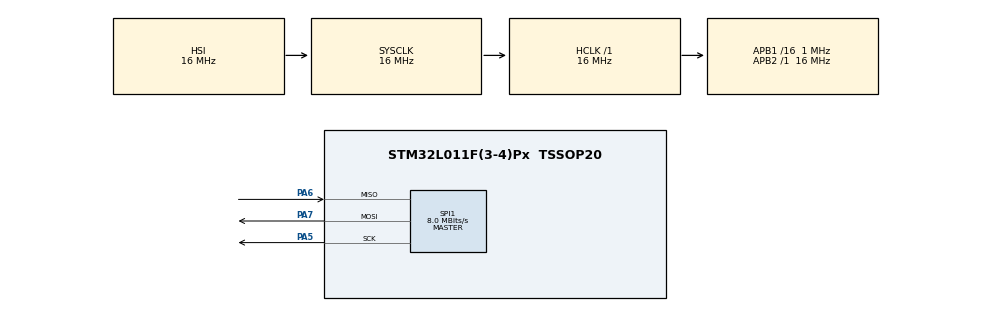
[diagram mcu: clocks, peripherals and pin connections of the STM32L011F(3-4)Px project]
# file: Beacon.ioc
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CRC.CRCLength=CRC_POLYLENGTH_8B
CRC.DefaultInitValueUse=DEFAULT_INIT_VALUE_DISABLE
CRC.DefaultPolynomialUse=DEFAULT_POLYNOMIAL_DISABLE
CRC.InitValue=0x00
CRC.InputDataFormat=CRC_INPUTDATA_FORMAT_BYTES
Mcu.Family=STM32L0
Mcu.Name=STM32L011F(3-4)Px
Mcu.Package=TSSOP20
NVIC.RTC_IRQn=true\:0\:0\:false\:false\:true\:true\:true
PA5.Mode=Full_Duplex_Master
PA5.Signal=SPI1_SCK
PA6.Mode=Full_Duplex_Master
PA6.Signal=SPI1_MISO
PA7.Mode=Full_Duplex_Master
PA7.Signal=SPI1_MOSI
ProjectManager.HeapSize=0x200
ProjectManager.StackSize=0x400
ProjectManager.TargetToolchain=STM32CubeIDE
RCC.AHBFreq_Value=16000000
RCC.APB1CLKDivider=RCC_HCLK_DIV16
RCC.APB1Freq_Value=1000000
RCC.APB1TimFreq_Value=2000000
RCC.APB2Freq_Value=16000000
RCC.APB2TimFreq_Value=16000000
RCC.HCLKFreq_Value=16000000
RCC.HSE_VALUE=8000000
RCC.HSI16_VALUE=16000000
RCC.HSI_VALUE=16000000
RCC.LSE_VALUE=32768
RCC.LptimClockSelection=RCC_LPTIM1CLKSOURCE_LSI
RCC.MSI_VALUE=2097000
RCC.SYSCLKFreq_VALUE=16000000
RCC.SYSCLKSource=RCC_SYSCLKSOURCE_HSI
RCC.VCOOutputFreq_Value=48000000
RTC.Alarm-Alarm\ A=RTC_ALARM_A
RTC.AlarmMaskDateWeekDay-Alarm\ A=RTC_ALARMMASK_DATEWEEKDAY
RTC.AlarmMaskHours-Alarm\ A=RTC_ALARMMASK_HOURS
RTC.AlarmMaskMinutes-Alarm\ A=RTC_ALARMMASK_MINUTES
RTC.AlarmMaskSeconds-Alarm\ A=RTC_ALARMMASK_SECONDS
RTC.Format=RTC_FORMAT_BIN
SPI1.CalculateBaudRate=8.0 MBits/s
SPI1.Direction=SPI_DIRECTION_2LINES
SPI1.Mode=SPI_MODE_MASTER
SPI1.VirtualType=VM_MASTER
VP_CRC_VS_CRC.Mode=CRC_Activate
VP_RTC_VS_RTC_Activate.Mode=RTC_Enabled
VP_RTC_VS_RTC_Alarm_A_Intern.Mode=Alarm A
VP_RTC_VS_RTC_Calendar.Mode=RTC_Calendar
board=custom

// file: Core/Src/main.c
/* USER CODE BEGIN Header */
/**
  ******************************************************************************
  * @file           : main.c
  * @brief          : Main program body
  ******************************************************************************
  * @attention
  *
  * <h2><center>&copy; Copyright (c) 2020 STMicroelectronics.
  * All rights reserved.</center></h2>
  *
  * This software component is licensed by ST under BSD 3-Clause license,
  * the "License"; You may not use this file except in compliance with the
  * License. You may obtain a copy of the License at:
  *                        opensource.org/licenses/BSD-3-Clause
  *
  ******************************************************************************
  */
/* USER CODE END Header */

#include "main.h"

/* USER CODE BEGIN Includes */
#include "program.h"
#include "nrf24.h"
/* USER CODE END Includes */

CRC_HandleTypeDef hcrc;

RTC_HandleTypeDef hrtc;

SPI_HandleTypeDef hspi1;

void SystemClock_Config(void);
static void MX_RTC_Init(void);
static void MX_GPIO_Init(void);
static void MX_SPI1_Init(void);
static void MX_CRC_Init(void);

int main(void)
{

  /* MCU Configuration--------------------------------------------------------*/

  /* Reset of all peripherals, Initializes the Flash interface and the Systick. */
  HAL_Init();

  /* Configure the system clock */
  SystemClock_Config();

  /* Initialize all configured peripherals */
  MX_RTC_Init();
  MX_GPIO_Init();
  MX_SPI1_Init();
  MX_CRC_Init();
  /* USER CODE BEGIN 2 */
  NRF24_Init();
  /* USER CODE END 2 */

  /* Infinite loop */
  /* USER CODE BEGIN WHILE */
  setup();
  while (1)
  {
    /* USER CODE END WHILE */

  }
}

void SystemClock_Config(void)
{
  RCC_OscInitTypeDef RCC_OscInitStruct = {0};
  RCC_ClkInitTypeDef RCC_ClkInitStruct = {0};
  RCC_PeriphCLKInitTypeDef PeriphClkInit = {0};

  /** Configure the main internal regulator output voltage
  */
  __HAL_PWR_VOLTAGESCALING_CONFIG(PWR_REGULATOR_VOLTAGE_SCALE1);
  /** Initializes the CPU, AHB and APB busses clocks
  */
  RCC_OscInitStruct.OscillatorType = RCC_OSCILLATORTYPE_HSI|RCC_OSCILLATORTYPE_LSI;
  RCC_OscInitStruct.HSIState = RCC_HSI_ON;
  RCC_OscInitStruct.HSICalibrationValue = RCC_HSICALIBRATION_DEFAULT;
  RCC_OscInitStruct.LSIState = RCC_LSI_ON;
  RCC_OscInitStruct.PLL.PLLState = RCC_PLL_NONE;
  if (HAL_RCC_OscConfig(&RCC_OscInitStruct) != HAL_OK)
  {
    Error_Handler();
  }
  /** Initializes the CPU, AHB and APB busses clocks
  */
  RCC_ClkInitStruct.ClockType = RCC_CLOCKTYPE_HCLK|RCC_CLOCKTYPE_SYSCLK
                              |RCC_CLOCKTYPE_PCLK1|RCC_CLOCKTYPE_PCLK2;
  RCC_ClkInitStruct.SYSCLKSource = RCC_SYSCLKSOURCE_HSI;
  RCC_ClkInitStruct.AHBCLKDivider = RCC_SYSCLK_DIV1;
  RCC_ClkInitStruct.APB1CLKDivider = RCC_HCLK_DIV16;
  RCC_ClkInitStruct.APB2CLKDivider = RCC_HCLK_DIV1;

  if (HAL_RCC_ClockConfig(&RCC_ClkInitStruct, FLASH_LATENCY_0) != HAL_OK)
  {
    Error_Handler();
  }
  PeriphClkInit.PeriphClockSelection = RCC_PERIPHCLK_RTC;
  PeriphClkInit.RTCClockSelection = RCC_RTCCLKSOURCE_LSI;
  if (HAL_RCCEx_PeriphCLKConfig(&PeriphClkInit) != HAL_OK)
  {
    Error_Handler();
  }
}

static void MX_CRC_Init(void)
{

  hcrc.Instance = CRC;
  hcrc.Init.DefaultPolynomialUse = DEFAULT_POLYNOMIAL_DISABLE;
  hcrc.Init.DefaultInitValueUse = DEFAULT_INIT_VALUE_DISABLE;
  hcrc.Init.GeneratingPolynomial = 7;
  hcrc.Init.CRCLength = CRC_POLYLENGTH_8B;
  hcrc.Init.InitValue = 0x00;
  hcrc.Init.InputDataInversionMode = CRC_INPUTDATA_INVERSION_NONE;
  hcrc.Init.OutputDataInversionMode = CRC_OUTPUTDATA_INVERSION_DISABLE;
  hcrc.InputDataFormat = CRC_INPUTDATA_FORMAT_BYTES;
  if (HAL_CRC_Init(&hcrc) != HAL_OK)
  {
    Error_Handler();
  }

}

static void MX_RTC_Init(void)
{

  RTC_TimeTypeDef sTime = {0};
  RTC_DateTypeDef sDate = {0};
  RTC_AlarmTypeDef sAlarm = {0};

  /** Initialize RTC Only
  */
  hrtc.Instance = RTC;
  hrtc.Init.HourFormat = RTC_HOURFORMAT_24;
  hrtc.Init.AsynchPrediv = 127;
  hrtc.Init.SynchPrediv = 255;
  hrtc.Init.OutPut = RTC_OUTPUT_DISABLE;
  hrtc.Init.OutPutRemap = RTC_OUTPUT_REMAP_NONE;
  hrtc.Init.OutPutPolarity = RTC_OUTPUT_POLARITY_HIGH;
  hrtc.Init.OutPutType = RTC_OUTPUT_TYPE_OPENDRAIN;
  if (HAL_RTC_Init(&hrtc) != HAL_OK)
  {
    Error_Handler();
  }

  /** Initialize RTC and set the Time and Date
  */
  sTime.Hours = 0;
  sTime.Minutes = 0;
  sTime.Seconds = 0;
  sTime.DayLightSaving = RTC_DAYLIGHTSAVING_NONE;
  sTime.StoreOperation = RTC_STOREOPERATION_RESET;
  if (HAL_RTC_SetTime(&hrtc, &sTime, RTC_FORMAT_BIN) != HAL_OK)
  {
    Error_Handler();
  }
  sDate.WeekDay = RTC_WEEKDAY_MONDAY;
  sDate.Month = RTC_MONTH_JANUARY;
  sDate.Date = 1;
  sDate.Year = 0;

  if (HAL_RTC_SetDate(&hrtc, &sDate, RTC_FORMAT_BIN) != HAL_OK)
  {
    Error_Handler();
  }
  /** Enable the Alarm A
  */
  sAlarm.AlarmTime.Hours = 0;
  sAlarm.AlarmTime.Minutes = 0;
  sAlarm.AlarmTime.Seconds = 0;
  sAlarm.AlarmTime.SubSeconds = 0;
  sAlarm.AlarmTime.DayLightSaving = RTC_DAYLIGHTSAVING_NONE;
  sAlarm.AlarmTime.StoreOperation = RTC_STOREOPERATION_RESET;
  sAlarm.AlarmMask = RTC_ALARMMASK_ALL;
  sAlarm.AlarmSubSecondMask = RTC_ALARMSUBSECONDMASK_ALL;
  sAlarm.AlarmDateWeekDaySel = RTC_ALARMDATEWEEKDAYSEL_DATE;
  sAlarm.AlarmDateWeekDay = 1;
  sAlarm.Alarm = RTC_ALARM_A;
  if (HAL_RTC_SetAlarm_IT(&hrtc, &sAlarm, RTC_FORMAT_BIN) != HAL_OK)
  {
    Error_Handler();
  }

}

static void MX_SPI1_Init(void)
{

  /* USER CODE BEGIN SPI1_Init 0 */
	return;
  /* USER CODE END SPI1_Init 0 */

  /* SPI1 parameter configuration*/
  hspi1.Instance = SPI1;
  hspi1.Init.Mode = SPI_MODE_MASTER;
  hspi1.Init.Direction = SPI_DIRECTION_2LINES;
  hspi1.Init.DataSize = SPI_DATASIZE_8BIT;
  hspi1.Init.CLKPolarity = SPI_POLARITY_LOW;
  hspi1.Init.CLKPhase = SPI_PHASE_1EDGE;
  hspi1.Init.NSS = SPI_NSS_SOFT;
  hspi1.Init.BaudRatePrescaler = SPI_BAUDRATEPRESCALER_2;
  hspi1.Init.FirstBit = SPI_FIRSTBIT_MSB;
  hspi1.Init.TIMode = SPI_TIMODE_DISABLE;
  hspi1.Init.CRCCalculation = SPI_CRCCALCULATION_DISABLE;
  hspi1.Init.CRCPolynomial = 7;
  if (HAL_SPI_Init(&hspi1) != HAL_OK)
  {
    Error_Handler();
  }

}

static void MX_GPIO_Init(void)
{

  /* GPIO Ports Clock Enable */
  __HAL_RCC_GPIOA_CLK_ENABLE();

}

void Error_Handler(void)
{
}

/************************ (C) COPYRIGHT STMicroelectronics *****END OF FILE****/
